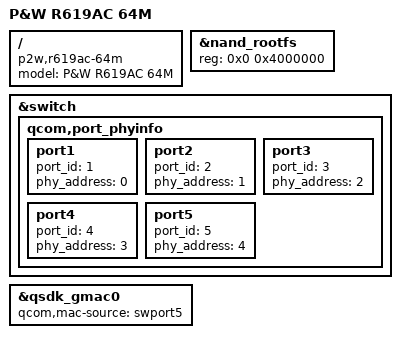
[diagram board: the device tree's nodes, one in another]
// SPDX-License-Identifier: GPL-2.0-or-later OR MIT

#include "qcom-ipq4019-r619ac.dtsi"

/ {
	model = "P&W R619AC 64M";
	compatible = "p2w,r619ac-64m";
};

&nand_rootfs {
	reg = <0x0 0x4000000>;
};

/* QSDK 10: retain this board's physical LAN/WAN port assignment. */
#define QSDK_LAN_BMP 0x1e
#define QSDK_WAN_BMP 0x20
#define QSDK_WAN_PHY 4
#define QSDK_WAN_POLL 1
#include "qcom-ipq40xx-qsdk-10.dtsi"

&switch {
	qcom,port_phyinfo {
		port1 { port_id = <1>; phy_address = <0>; };
		port2 { port_id = <2>; phy_address = <1>; };
		port3 { port_id = <3>; phy_address = <2>; };
		port4 { port_id = <4>; phy_address = <3>; };
		port5 { port_id = <5>; phy_address = <4>; };
	};
};

&qsdk_gmac0 {
	qcom,mac-source = <&swport5>;
};
